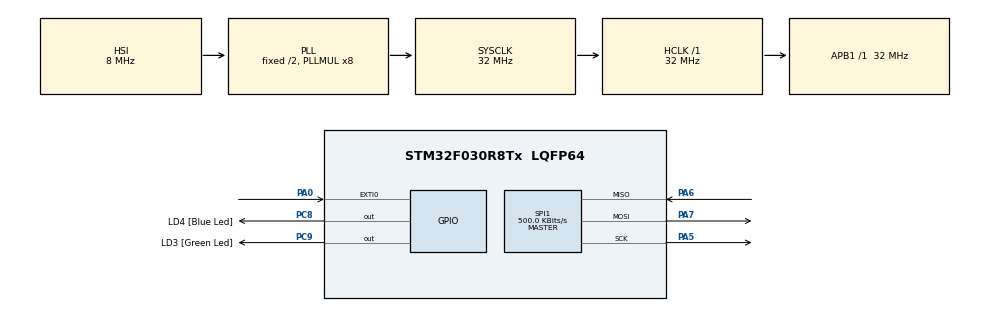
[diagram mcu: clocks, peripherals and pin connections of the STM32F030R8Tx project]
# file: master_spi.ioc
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Mcu.Family=STM32F0
Mcu.Name=STM32F030R8Tx
Mcu.Package=LQFP64
NVIC.EXTI0_1_IRQn=true\:0\:0\:false\:false\:true\:true\:true
NVIC.SPI1_IRQn=true\:0\:0\:false\:false\:true\:true\:true
PA0.Signal=GPXTI0
PA13.GPIO_Label=SWDIO
PA13.Mode=Serial_Wire
PA13.Signal=SYS_SWDIO
PA14.GPIO_Label=SWCLK
PA14.Mode=Serial_Wire
PA14.Signal=SYS_SWCLK
PA5.Mode=Full_Duplex_Master
PA5.Signal=SPI1_SCK
PA6.Mode=Full_Duplex_Master
PA6.Signal=SPI1_MISO
PA7.Mode=Full_Duplex_Master
PA7.Signal=SPI1_MOSI
PC8.GPIO_Label=LD4 [Blue Led]
PC8.Signal=GPIO_Output
PC9.GPIO_Label=LD3 [Green Led]
PC9.Signal=GPIO_Output
ProjectManager.HeapSize=0x200
ProjectManager.StackSize=0x400
ProjectManager.TargetToolchain=MDK-ARM V5
RCC.AHBFreq_Value=32000000
RCC.APB1Freq_Value=32000000
RCC.APB1TimFreq_Value=32000000
RCC.HCLKFreq_Value=32000000
RCC.PLLMUL=RCC_PLL_MUL8
RCC.SYSCLKFreq_VALUE=32000000
RCC.SYSCLKSource=RCC_SYSCLKSOURCE_PLLCLK
SPI1.BaudRatePrescaler=SPI_BAUDRATEPRESCALER_64
SPI1.CLKPhase=SPI_PHASE_2EDGE
SPI1.CLKPolarity=SPI_POLARITY_LOW
SPI1.CalculateBaudRate=500.0 KBits/s
SPI1.DataSize=SPI_DATASIZE_8BIT
SPI1.Direction=SPI_DIRECTION_2LINES
SPI1.Mode=SPI_MODE_MASTER
SPI1.VirtualType=VM_MASTER
board=32F0308DISCOVERY

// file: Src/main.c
/* USER CODE BEGIN Header */
/**
  ******************************************************************************
  * @file           : main.c
  * @brief          : Main program body
  ******************************************************************************
  * @attention
  *
  * <h2><center>&copy; Copyright (c) 2020 STMicroelectronics.
  * All rights reserved.</center></h2>
  *
  * This software component is licensed by ST under BSD 3-Clause license,
  * the "License"; You may not use this file except in compliance with the
  * License. You may obtain a copy of the License at:
  *                        opensource.org/licenses/BSD-3-Clause
  *
  ******************************************************************************
  */
/* USER CODE END Header */

#include "main.h"

SPI_HandleTypeDef hspi1;

void SystemClock_Config(void);
static void MX_GPIO_Init(void);
static void MX_SPI1_Init(void);

/* USER CODE BEGIN 0 */
uint8_t IS_Button_Press=0;

uint8_t Send_data[4]={0xA1,0xA2,0xA3,0xA4};
uint8_t ack_bytes;
uint8_t Write_Cmd =0x6A;
/* USER CODE END 0 */

int main(void)
{

  /* MCU Configuration--------------------------------------------------------*/

  /* Reset of all peripherals, Initializes the Flash interface and the Systick. */
  HAL_Init();

  /* Configure the system clock */
  SystemClock_Config();

  /* Initialize all configured peripherals */
  MX_GPIO_Init();
  MX_SPI1_Init();
  /* USER CODE BEGIN 2 */
   while(IS_Button_Press!=1)
	 {
		 HAL_GPIO_TogglePin(GPIOC,GPIO_PIN_9);
		 HAL_GPIO_TogglePin(GPIOC,GPIO_PIN_8);
		 HAL_Delay(500);
	 }
	 HAL_GPIO_WritePin(GPIOC, LD4_Pin|LD3_Pin, GPIO_PIN_RESET);
	 HAL_SPI_Transmit_IT(&hspi1,&Write_Cmd,1);
  /* USER CODE END 2 */

  /* Infinite loop */
  while (1)
  {

  }
}

void HAL_SPI_TxCpltCallback(SPI_HandleTypeDef *hspi)
{
   HAL_GPIO_WritePin(GPIOC,GPIO_PIN_9,1);
	 HAL_GPIO_WritePin(GPIOC,GPIO_PIN_8,1);
}
void SystemClock_Config(void)
{
  RCC_OscInitTypeDef RCC_OscInitStruct = {0};
  RCC_ClkInitTypeDef RCC_ClkInitStruct = {0};

  /** Initializes the CPU, AHB and APB busses clocks
  */
  RCC_OscInitStruct.OscillatorType = RCC_OSCILLATORTYPE_HSI;
  RCC_OscInitStruct.HSIState = RCC_HSI_ON;
  RCC_OscInitStruct.HSICalibrationValue = RCC_HSICALIBRATION_DEFAULT;
  RCC_OscInitStruct.PLL.PLLState = RCC_PLL_ON;
  RCC_OscInitStruct.PLL.PLLSource = RCC_PLLSOURCE_HSI;
  RCC_OscInitStruct.PLL.PLLMUL = RCC_PLL_MUL8;
  RCC_OscInitStruct.PLL.PREDIV = RCC_PREDIV_DIV1;
  if (HAL_RCC_OscConfig(&RCC_OscInitStruct) != HAL_OK)
  {
    Error_Handler();
  }
  /** Initializes the CPU, AHB and APB busses clocks
  */
  RCC_ClkInitStruct.ClockType = RCC_CLOCKTYPE_HCLK|RCC_CLOCKTYPE_SYSCLK
                              |RCC_CLOCKTYPE_PCLK1;
  RCC_ClkInitStruct.SYSCLKSource = RCC_SYSCLKSOURCE_PLLCLK;
  RCC_ClkInitStruct.AHBCLKDivider = RCC_SYSCLK_DIV1;
  RCC_ClkInitStruct.APB1CLKDivider = RCC_HCLK_DIV1;

  if (HAL_RCC_ClockConfig(&RCC_ClkInitStruct, FLASH_LATENCY_1) != HAL_OK)
  {
    Error_Handler();
  }
}

static void MX_SPI1_Init(void)
{

  /* SPI1 parameter configuration*/
  hspi1.Instance = SPI1;
  hspi1.Init.Mode = SPI_MODE_MASTER;
  hspi1.Init.Direction = SPI_DIRECTION_2LINES;
  hspi1.Init.DataSize = SPI_DATASIZE_8BIT;
  hspi1.Init.CLKPolarity = SPI_POLARITY_LOW;
  hspi1.Init.CLKPhase = SPI_PHASE_2EDGE;
  hspi1.Init.NSS = SPI_NSS_SOFT;
  hspi1.Init.BaudRatePrescaler = SPI_BAUDRATEPRESCALER_64;
  hspi1.Init.FirstBit = SPI_FIRSTBIT_MSB;
  hspi1.Init.TIMode = SPI_TIMODE_DISABLE;
  hspi1.Init.CRCCalculation = SPI_CRCCALCULATION_DISABLE;
  hspi1.Init.CRCPolynomial = 7;
  hspi1.Init.CRCLength = SPI_CRC_LENGTH_DATASIZE;
  hspi1.Init.NSSPMode = SPI_NSS_PULSE_DISABLE;
  if (HAL_SPI_Init(&hspi1) != HAL_OK)
  {
    Error_Handler();
  }

}

static void MX_GPIO_Init(void)
{
  GPIO_InitTypeDef GPIO_InitStruct = {0};

  /* GPIO Ports Clock Enable */
  __HAL_RCC_GPIOA_CLK_ENABLE();
  __HAL_RCC_GPIOC_CLK_ENABLE();

  /*Configure GPIO pin Output Level */
  HAL_GPIO_WritePin(GPIOC, LD4_Pin|LD3_Pin, GPIO_PIN_RESET);

  /*Configure GPIO pin : PA0 */
  GPIO_InitStruct.Pin = GPIO_PIN_0;
  GPIO_InitStruct.Mode = GPIO_MODE_IT_RISING;
  GPIO_InitStruct.Pull = GPIO_NOPULL;
  HAL_GPIO_Init(GPIOA, &GPIO_InitStruct);

  /*Configure GPIO pins : LD4_Pin LD3_Pin */
  GPIO_InitStruct.Pin = LD4_Pin|LD3_Pin;
  GPIO_InitStruct.Mode = GPIO_MODE_OUTPUT_PP;
  GPIO_InitStruct.Pull = GPIO_NOPULL;
  GPIO_InitStruct.Speed = GPIO_SPEED_FREQ_LOW;
  HAL_GPIO_Init(GPIOC, &GPIO_InitStruct);

  /* EXTI interrupt init*/
  HAL_NVIC_SetPriority(EXTI0_1_IRQn, 0, 0);
  HAL_NVIC_EnableIRQ(EXTI0_1_IRQn);

}

void Error_Handler(void)
{
}

/************************ (C) COPYRIGHT STMicroelectronics *****END OF FILE****/
